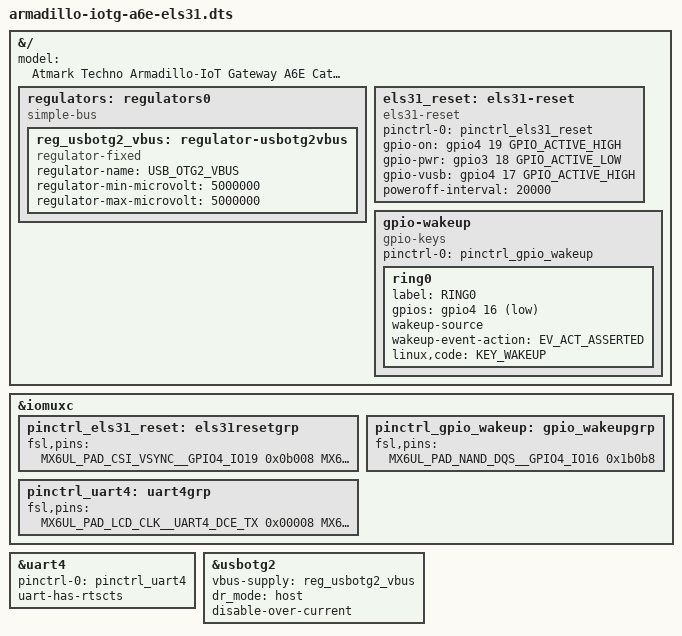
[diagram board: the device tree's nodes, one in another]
// SPDX-License-Identifier: (GPL-2.0 OR MIT)
/*
 * Copyright (C) 2022 Atmark Techno, Inc. All Rights Reserved.
 */

/dts-v1/;
/plugin/;

#include <dt-bindings/gpio/gpio.h>
#include <dt-bindings/input/input.h>
#include <dt-bindings/input/gpio-keys.h>
#include "imx6ull-pinfunc.h"
#include "imx6ull-pinfunc-snvs.h"

&{/} {
	model = "Atmark Techno Armadillo-IoT Gateway A6E Cat.1 Board";

	regulators: regulators0 {
		compatible = "simple-bus";
		#address-cells = <1>;
		#size-cells = <0>;

		reg_usbotg2_vbus: regulator-usbotg2vbus {
			compatible = "regulator-fixed";
			regulator-name = "USB_OTG2_VBUS";
			regulator-min-microvolt = <5000000>;
			regulator-max-microvolt = <5000000>;
                };
        };

	els31_reset: els31-reset {
		compatible = "els31-reset";
		pinctrl-names = "default";
		pinctrl-0 = <&pinctrl_els31_reset>;
		gpio-on = <&gpio4 19 GPIO_ACTIVE_HIGH>;
		gpio-pwr = <&gpio3 18 GPIO_ACTIVE_LOW>;
		gpio-vusb = <&gpio4 17 GPIO_ACTIVE_HIGH>;
		poweroff-interval = <20000>; /* 20 sec */
	};

	gpio-wakeup {
		compatible = "gpio-keys";
		pinctrl-names = "default";
		pinctrl-0 = <&pinctrl_gpio_wakeup>;

		ring0 {
			label = "RING0";
			gpios = <&gpio4 16 GPIO_ACTIVE_LOW>;
			wakeup-source;
			wakeup-event-action = <EV_ACT_ASSERTED>;
			linux,code = <KEY_WAKEUP>;
		};
	};
};

&iomuxc {
	pinctrl_els31_reset: els31resetgrp {
		fsl,pins = <
			MX6UL_PAD_CSI_VSYNC__GPIO4_IO19		0x0b008 /* BAT_LTE_ON */
			MX6UL_PAD_LCD_DATA13__GPIO3_IO18	0x0b008 /* VCC_4.4V_LTE */
			MX6UL_PAD_CSI_MCLK__GPIO4_IO17		0x0b008 /* ELS31 VUSB */
		>;
	};

	pinctrl_uart4: uart4grp {
		fsl,pins= <
			MX6UL_PAD_LCD_CLK__UART4_DCE_TX		0x00008 /* ELS31 TXD0 */
			MX6UL_PAD_LCD_ENABLE__UART4_DCE_RX	0x1b0b1 /* ELS31 RXD0 */
			MX6UL_PAD_LCD_HSYNC__UART4_DCE_CTS	0x00008 /* ELS31 CTS0 */
			MX6UL_PAD_LCD_VSYNC__UART4_DCE_RTS	0x1b0b1 /* ELS31 RTS0 */
		>;
	};

	pinctrl_gpio_wakeup: gpio_wakeupgrp {
		fsl,pins = <
			MX6UL_PAD_NAND_DQS__GPIO4_IO16	0x1b0b8 /* ELS31 RING0 */
		>;
	};
};

/* ELS31(LTE) */
&uart4 {
	pinctrl-names = "default";
	pinctrl-0 = <&pinctrl_uart4>;
	status = "okay";
	uart-has-rtscts;
};

&usbotg2 {
	vbus-supply = <&reg_usbotg2_vbus>;
	dr_mode = "host";
	disable-over-current;
	status = "okay";
};
